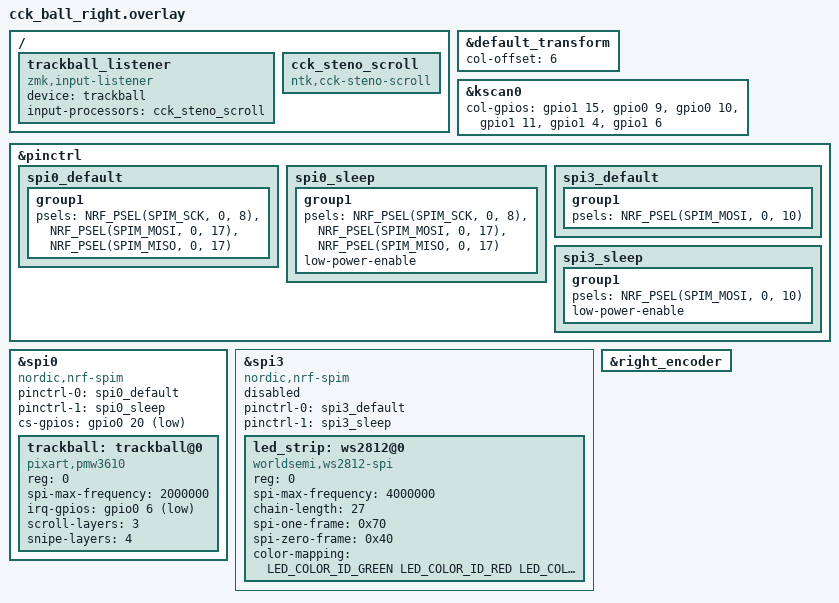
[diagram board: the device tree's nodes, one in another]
/*
 * Copyright (c) 2020 ZMK Contributors
 * SPDX-License-Identifier: MIT
 */

#include "cck_ball.dtsi"

&default_transform {
    col-offset = <6>;
};

&kscan0 {
    col-gpios
        = <&gpio1 15 GPIO_ACTIVE_HIGH>
        , <&gpio0 9 GPIO_ACTIVE_HIGH>
        , <&gpio0 10 GPIO_ACTIVE_HIGH>
        , <&gpio1 11 GPIO_ACTIVE_HIGH>
        , <&gpio1 4 GPIO_ACTIVE_HIGH>
        , <&gpio1 6 GPIO_ACTIVE_HIGH>
        ;
};

// PMW3610 trackball.
&pinctrl {
    spi0_default: spi0_default {
        group1 {
            psels = <NRF_PSEL(SPIM_SCK, 0, 8)>,
                    <NRF_PSEL(SPIM_MOSI, 0, 17)>,
                    <NRF_PSEL(SPIM_MISO, 0, 17)>;
        };
    };

    spi0_sleep: spi0_sleep {
        group1 {
            psels = <NRF_PSEL(SPIM_SCK, 0, 8)>,
                    <NRF_PSEL(SPIM_MOSI, 0, 17)>,
                    <NRF_PSEL(SPIM_MISO, 0, 17)>;
            low-power-enable;
        };
    };
};

&spi0 {
    status = "okay";
    compatible = "nordic,nrf-spim";
    pinctrl-0 = <&spi0_default>;
    pinctrl-1 = <&spi0_sleep>;
    pinctrl-names = "default", "sleep";
    cs-gpios = <&gpio0 20 GPIO_ACTIVE_LOW>;

    trackball: trackball@0 {
        status = "okay";
        compatible = "pixart,pmw3610";
        reg = <0>;
        spi-max-frequency = <2000000>;
        irq-gpios = <&gpio0 6 (GPIO_ACTIVE_LOW | GPIO_PULL_UP)>;
        scroll-layers = <3>;
        snipe-layers = <4>;
        // automouse-layer = <3>;
    };
};

// RGB bus retained from CCK-BALL.
&pinctrl {
    spi3_default: spi3_default {
        group1 {
            psels = <NRF_PSEL(SPIM_MOSI, 0, 10)>;
        };
    };
    spi3_sleep: spi3_sleep {
        group1 {
            psels = <NRF_PSEL(SPIM_MOSI, 0, 10)>;
            low-power-enable;
        };
    };
};

&spi3 {
    compatible = "nordic,nrf-spim";
    status = "okay";

    pinctrl-0 = <&spi3_default>;
    pinctrl-1 = <&spi3_sleep>;
    pinctrl-names = "default", "sleep";

    led_strip: ws2812@0 {
        compatible = "worldsemi,ws2812-spi";
        reg = <0>;
        spi-max-frequency = <4000000>;
        chain-length = <27>;
        spi-one-frame = <0x70>;
        spi-zero-frame = <0x40>;
        color-mapping = <LED_COLOR_ID_GREEN
                         LED_COLOR_ID_RED
                         LED_COLOR_ID_BLUE>;
    };
};

/ {
    trackball_listener {
        compatible = "zmk,input-listener";
        device = <&trackball>;
        input-processors = <&cck_steno_scroll>;
    };
};

&right_encoder {
    status = "okay";
};

/* Legacy unused RGB SPI3 shared P0.10 with a matrix column.
 * Keep the LED description for provenance but do not claim that pin at boot.
 * No RGB feature is enabled in this STENO build. */
&spi3 { status = "disabled"; };

/ {
    cck_steno_scroll: cck_steno_scroll {
        compatible = "ntk,cck-steno-scroll";
        #input-processor-cells = <0>;
        status = "okay";
    };
};
